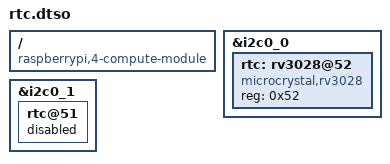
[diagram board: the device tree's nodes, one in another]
/*
 * DT overlay for enabling the on-board Micro Crystal RV-3028 RTC on the Exaviz
 * Interceptor carrier board v1.0 for the Raspberry Pi Compute Module 4, and
 * disabling the NXP PCF85063A RTC on the Raspberry Pi Compute Module 4 IO
 * Board.
 */

/dts-v1/;
/plugin/;

/ {
	compatible = "raspberrypi,4-compute-module";
};

&i2c0_0 {
	rtc: rv3028@52 {
		compatible = "microcrystal,rv3028";
		reg = <0x52>;
	};
};

&i2c0_1 {
	rtc@51 {
		status = "disabled";
	};
};
